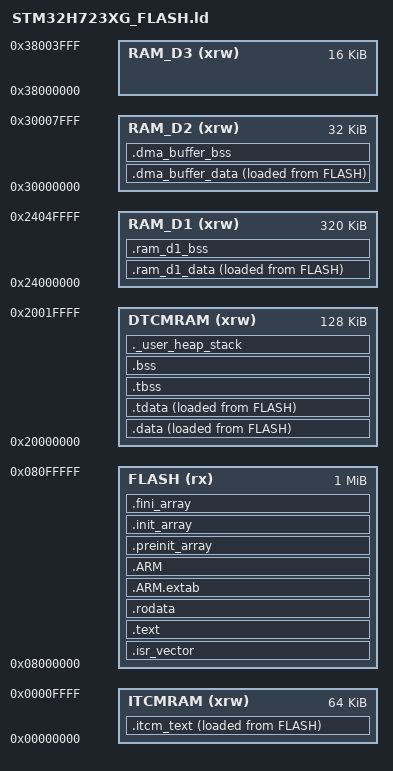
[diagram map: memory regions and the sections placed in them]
/*
******************************************************************************
**

**  File        : LinkerScript.ld
**
**  Author		: STM32CubeMX
**
**  Abstract    : Linker script for STM32H723ZGTx series
**                1024Kbytes FLASH and 560Kbytes RAM
**
**                Set heap size, stack size and stack location according
**                to application requirements.
**
**                Set memory bank area and size if external memory is used.
**
**  Target      : STMicroelectronics STM32
**
**  Distribution: The file is distributed “as is,” without any warranty
**                of any kind.
**
*****************************************************************************
** @attention
**
** <h2><center>&copy; COPYRIGHT(c) 2025 STMicroelectronics</center></h2>
**
** Redistribution and use in source and binary forms, with or without modification,
** are permitted provided that the following conditions are met:
**   1. Redistributions of source code must retain the above copyright notice,
**      this list of conditions and the following disclaimer.
**   2. Redistributions in binary form must reproduce the above copyright notice,
**      this list of conditions and the following disclaimer in the documentation
**      and/or other materials provided with the distribution.
**   3. Neither the name of STMicroelectronics nor the names of its contributors
**      may be used to endorse or promote products derived from this software
**      without specific prior written permission.
**
** THIS SOFTWARE IS PROVIDED BY THE COPYRIGHT HOLDERS AND CONTRIBUTORS "AS IS"
** AND ANY EXPRESS OR IMPLIED WARRANTIES, INCLUDING, BUT NOT LIMITED TO, THE
** IMPLIED WARRANTIES OF MERCHANTABILITY AND FITNESS FOR A PARTICULAR PURPOSE ARE
** DISCLAIMED. IN NO EVENT SHALL THE COPYRIGHT HOLDER OR CONTRIBUTORS BE LIABLE
** FOR ANY DIRECT, INDIRECT, INCIDENTAL, SPECIAL, EXEMPLARY, OR CONSEQUENTIAL
** DAMAGES (INCLUDING, BUT NOT LIMITED TO, PROCUREMENT OF SUBSTITUTE GOODS OR
** SERVICES; LOSS OF USE, DATA, OR PROFITS; OR BUSINESS INTERRUPTION) HOWEVER
** CAUSED AND ON ANY THEORY OF LIABILITY, WHETHER IN CONTRACT, STRICT LIABILITY,
** OR TORT (INCLUDING NEGLIGENCE OR OTHERWISE) ARISING IN ANY WAY OUT OF THE USE
** OF THIS SOFTWARE, EVEN IF ADVISED OF THE POSSIBILITY OF SUCH DAMAGE.
**
*****************************************************************************
*/

/* Entry Point */
ENTRY(Reset_Handler)

/* Specify the memory areas */
MEMORY
{
DTCMRAM (xrw)      : ORIGIN = 0x20000000, LENGTH = 128K
RAM_D1 (xrw)      : ORIGIN = 0x24000000, LENGTH = 320K
RAM_D2 (xrw)      : ORIGIN = 0x30000000, LENGTH = 32K
RAM_D3 (xrw)      : ORIGIN = 0x38000000, LENGTH = 16K
ITCMRAM (xrw)      : ORIGIN = 0x00000000, LENGTH = 64K
FLASH (rx)      : ORIGIN = 0x8000000, LENGTH = 1024K
}

/* Highest address of the user mode stack */
_estack = ORIGIN(DTCMRAM) + LENGTH(DTCMRAM);    /* end of RAM */
_sstack = _estack - _Min_Stack_Size;
/* Generate a link error if heap and stack don't fit into RAM */
_Min_Heap_Size = 0x1000;      /* required amount of heap  */
_Min_Stack_Size = 0x1500; /* required amount of stack */

/* Define output sections */
SECTIONS
{
  /* The startup code goes first into FLASH */
  .isr_vector :
  {
    . = ALIGN(4);
    KEEP(*(.isr_vector)) /* Startup code */
    . = ALIGN(4);
  } >FLASH

  /* The program code and other data goes into FLASH */
  .text :
  {
    . = ALIGN(4);
    *(.text)           /* .text sections (code) */
    *(.text*)          /* .text* sections (code) */
    *(.glue_7)         /* glue arm to thumb code */
    *(.glue_7t)        /* glue thumb to arm code */
    *(.eh_frame)

    KEEP (*(.init))
    KEEP (*(.fini))

    . = ALIGN(4);
    _etext = .;        /* define a global symbols at end of code */
  } >FLASH

  /* Critical hot functions executed from ITCM (load from FLASH at startup) */
  .itcm_text :
  {
    . = ALIGN(4);
    _sitcm = .;
    *(.itcm_text)
    *(.itcm_text*)
    . = ALIGN(4);
    _eitcm = .;
  } >ITCMRAM AT> FLASH

  _siitcm = LOADADDR(.itcm_text);

  /* Constant data goes into FLASH */
  .rodata :
  {
    . = ALIGN(4);
    *(.rodata)         /* .rodata sections (constants, strings, etc.) */
    *(.rodata*)        /* .rodata* sections (constants, strings, etc.) */
    . = ALIGN(4);
  } >FLASH

  .ARM.extab (READONLY) : /* The "READONLY" keyword is only supported in GCC11 and later, remove it if using GCC10 or earlier. */
  {
    . = ALIGN(4);
    *(.ARM.extab* .gnu.linkonce.armextab.*)
    . = ALIGN(4);
  } >FLASH

  .ARM (READONLY) : /* The "READONLY" keyword is only supported in GCC11 and later, remove it if using GCC10 or earlier. */
  {
    . = ALIGN(4);
    __exidx_start = .;
    *(.ARM.exidx*)
    __exidx_end = .;
    . = ALIGN(4);
  } >FLASH

  .preinit_array (READONLY) : /* The "READONLY" keyword is only supported in GCC11 and later, remove it if using GCC10 or earlier. */
  {
    . = ALIGN(4);
    PROVIDE_HIDDEN (__preinit_array_start = .);
    KEEP (*(.preinit_array*))
    PROVIDE_HIDDEN (__preinit_array_end = .);
    . = ALIGN(4);
  } >FLASH

  .init_array (READONLY) : /* The "READONLY" keyword is only supported in GCC11 and later, remove it if using GCC10 or earlier. */
  {
    . = ALIGN(4);
    PROVIDE_HIDDEN (__init_array_start = .);
    KEEP (*(SORT(.init_array.*)))
    KEEP (*(.init_array*))
    PROVIDE_HIDDEN (__init_array_end = .);
    . = ALIGN(4);
  } >FLASH

  .fini_array (READONLY) : /* The "READONLY" keyword is only supported in GCC11 and later, remove it if using GCC10 or earlier. */
  {
    . = ALIGN(4);
    PROVIDE_HIDDEN (__fini_array_start = .);
    KEEP (*(SORT(.fini_array.*)))
    KEEP (*(.fini_array*))
    PROVIDE_HIDDEN (__fini_array_end = .);
    . = ALIGN(4);
  } >FLASH

  /* used by the startup to initialize data */
  _sidata = LOADADDR(.data);

  /* Initialized data sections goes into RAM, load LMA copy after code */
  .data :
  {
    . = ALIGN(4);
    _sdata = .;        /* create a global symbol at data start */
    *(.data)           /* .data sections */
    *(.data*)          /* .data* sections */
    *(.RamFunc)        /* .RamFunc sections */
    *(.RamFunc*)       /* .RamFunc* sections */

    . = ALIGN(4);
  } >DTCMRAM AT> FLASH

 /* Initialized TLS data section */
  .tdata : ALIGN(4)
  {
    *(.tdata .tdata.* .gnu.linkonce.td.*)
    . = ALIGN(4);
    _edata = .;        /* define a global symbol at data end */
    PROVIDE(__data_end = .);
    PROVIDE(__tdata_end = .);
  } >DTCMRAM AT> FLASH

  PROVIDE( __tdata_start = ADDR(.tdata) );
  PROVIDE( __tdata_size = __tdata_end - __tdata_start );

  PROVIDE( __data_start = ADDR(.data) );
  PROVIDE( __data_size = __data_end - __data_start );

  PROVIDE( __tdata_source = LOADADDR(.tdata) );
  PROVIDE( __tdata_source_end = LOADADDR(.tdata) + SIZEOF(.tdata) );
  PROVIDE( __tdata_source_size = __tdata_source_end - __tdata_source );

  PROVIDE( __data_source = LOADADDR(.data) );
  PROVIDE( __data_source_end = __tdata_source_end );
  PROVIDE( __data_source_size = __data_source_end - __data_source );
  /* Uninitialized data section */
  .tbss (NOLOAD) : ALIGN(4)
  {
     /* This is used by the startup in order to initialize the .bss secion */
    _sbss = .;         /* define a global symbol at bss start */
    __bss_start__ = _sbss;
    *(.tbss .tbss.*)
    . = ALIGN(4);
    PROVIDE( __tbss_end = . );
  } >DTCMRAM

  PROVIDE( __tbss_start = ADDR(.tbss) );
  PROVIDE( __tbss_size = __tbss_end - __tbss_start );
  PROVIDE( __tbss_offset = ADDR(.tbss) - ADDR(.tdata) );

  PROVIDE( __tls_base = __tdata_start );
  PROVIDE( __tls_end = __tbss_end );
  PROVIDE( __tls_size = __tls_end - __tls_base );
  PROVIDE( __tls_align = MAX(ALIGNOF(.tdata), ALIGNOF(.tbss)) );
  PROVIDE( __tls_size_align = (__tls_size + __tls_align - 1) & ~(__tls_align - 1) );
  PROVIDE( __arm32_tls_tcb_offset = MAX(8, __tls_align) );
  PROVIDE( __arm64_tls_tcb_offset = MAX(16, __tls_align) );

  .bss (NOLOAD) : ALIGN(4)
  {
    *(.bss)
    *(.bss*)
    *(COMMON)

      . = ALIGN(4);
    _ebss = .;         /* define a global symbol at bss end */
    __bss_end__ = _ebss;
      PROVIDE( __bss_end = .);
  } >DTCMRAM
  PROVIDE( __non_tls_bss_start = ADDR(.bss) );

  /* D2 SRAM：DATA 的初值存于 Flash，启动时复制到 DMA 可访问的内存。 */
  .dma_buffer_data : ALIGN(32)
  {
    _sdma_buffer_data = .;
    *(.dma_buffer_data)
    *(.dma_buffer_data.*)
    . = ALIGN(32);
    _edma_buffer_data = .;
  } >RAM_D2 AT> FLASH
  _sidma_buffer_data = LOADADDR(.dma_buffer_data);

  /* D2 BSS 不占用 Flash 初值空间，启动时由 Reset_Handler 清零。 */
  .dma_buffer_bss (NOLOAD) : ALIGN(32)
  {
    _sdma_buffer_bss = .;
    *(.dma_buffer_bss)
    *(.dma_buffer_bss.*)
    /*
     * RC27-TR2 USART3 PID Viewer 无回包复盘：下位机收到查询并生成了回复，但 TX 缓冲区
     * 在最终 ELF 中丢失，发送代码引用的缓冲区地址变成了 0。
     * 当时 UartPortDma 的 static inline 模板缓冲区共用 .dma_buffer_bss 输入段。
     * ARM GCC 给 robot.cpp.obj 和 debug_task.cpp.obj 的该段生成了相同的 COMDAT
     * 签名（RS485 TX），但只有后者包含 USART3 TX。链接器按整组去重时将它一起丢弃。
     *
     * DMA_BUFFER_BSS_UNIQUE 在 GCC 下用 noinit 配合 -fdata-sections，让每个模板
     * 缓冲区有独立的 .noinit.* 输入段和 COMDAT 签名。这里按通用前缀收集这些段，
     * 保留 32 字节对齐并放入 DMA 可访问的 D2 SRAM。虽然输入段叫 noinit，项目的
     * Reset_Handler 仍会清零整个 _sdma_buffer_bss 到 _edma_buffer_bss 区间。
     *
     * 工具链升级后可用 readelf -g 检查 .obj 的 COMDAT 分组，再核对最终 ELF/map
     * 中各路 DMA TX/RX 符号均位于 D2 SRAM 且地址满足对齐要求。当前 ARM GCC 的
     * 汇编器可能报告 .noinit.* 段类型警告，最终 .dma_buffer_bss 应为 NOBITS。
     *
     * TODO: 在构建结束时自动检查每个已启用的 UART DMA TX/RX 缓冲区。符号缺失、
     * 超出 D2 SRAM 或未按 32 字节对齐时直接报错。检查应覆盖本次 TX 符号被丢弃的情况。
     * TODO: 如需新增跨复位保留的数据，先提供专用内存宏和独立段，并确保该段在
     * Reset_Handler 的清零范围之外。当前规则会把 .noinit.* 收进启动时清零的 DMA 段。
     */
    *(.noinit.*)
    . = ALIGN(32);
    _edma_buffer_bss = .;
  } >RAM_D2

  /* D1 AXI SRAM：DATA 的初值存于 Flash，启动时复制到 RAM。 */
  .ram_d1_data : ALIGN(8)
  {
    _sram_d1_data = .;
    *(.ram_d1_data)
    *(.ram_d1_data.*)
    . = ALIGN(8);
    _eram_d1_data = .;
  } >RAM_D1 AT> FLASH
  _siram_d1_data = LOADADDR(.ram_d1_data);

  /* D1 BSS 不占用 Flash 初值空间，启动时由 Reset_Handler 清零。 */
  .ram_d1_bss (NOLOAD) : ALIGN(8)
  {
    _sram_d1_bss = .;
    *(.ram_d1_bss)
    *(.ram_d1_bss.*)
    . = ALIGN(8);
    _eram_d1_bss = .;
  } >RAM_D1

  PROVIDE( __bss_start = __tbss_start );
  PROVIDE( __bss_size = __bss_end - __bss_start );

  /* User_heap_stack section, used to check that there is enough RAM left */
  ._user_heap_stack (NOLOAD) :
  {
    . = ALIGN(8);
    PROVIDE ( end = . );
    PROVIDE ( _end = . );
    . = . + _Min_Heap_Size;
    . = . + _Min_Stack_Size;
    . = ALIGN(8);
  } >DTCMRAM



  /* Remove information from the standard libraries */
  /DISCARD/ :
  {
    libc.a:* ( * )
    libm.a:* ( * )
    libgcc.a:* ( * )
  }

}
